VERSION ""

NS_ :

BS_:

BU_: BMS_CARRIER CENTRE_CONSOLE POWER_DISTRIBUTION_REAR POWER_DISTRIBUTION_FRONT MOTOR_CONTROLLER PEDAL STEERING SOLAR CHARGER IMU POWER_SELECTION BABYDRIVER

BO_ 1 BPS_HEARTBEAT: 1 BMS_CARRIER
 SG_ status : 0|8@1+ (1,0) [0|0] "" Vector__XXX

BO_ 18 BPS_HEARTBEAT_ACK_FROM_CENTRE_CONSOLE: 1 CENTRE_CONSOLE
 SG_ BPS_HEARTBEAT_FROM_CENTRE_CONSOLE_ACK_STATUS : 0|8@1+ (1,0) [0|0] "" Vector__XXX

BO_ 34 SET_RELAY_STATES: 4 CENTRE_CONSOLE
 SG_ relay_state : 16|16@1+ (1,0) [0|0] "" Vector__XXX
 SG_ relay_mask : 0|16@1+ (1,0) [0|0] "" Vector__XXX

BO_ 49 SET_RELAY_STATES_ACK_FROM_BMS_CARRIER: 1 BMS_CARRIER
 SG_ SET_RELAY_STATES_FROM_BMS_CARRIER_ACK_STATUS : 0|8@1+ (1,0) [0|0] "" Vector__XXX

BO_ 56 SET_RELAY_STATES_ACK_FROM_SOLAR: 1 SOLAR
 SG_ SET_RELAY_STATES_FROM_SOLAR_ACK_STATUS : 0|8@1+ (1,0) [0|0] "" Vector__XXX

BO_ 53 SET_RELAY_STATES_ACK_FROM_MOTOR_CONTROLLER: 1 MOTOR_CONTROLLER
 SG_ SET_RELAY_STATES_FROM_MOTOR_CONTROLLER_ACK_STATUS : 0|8@1+ (1,0) [0|0] "" Vector__XXX

BO_ 98 POWERTRAIN_HEARTBEAT: 0 CENTRE_CONSOLE

BO_ 117 POWERTRAIN_HEARTBEAT_ACK_FROM_MOTOR_CONTROLLER: 1 MOTOR_CONTROLLER
 SG_ POWERTRAIN_HEARTBEAT_FROM_MOTOR_CONTROLLER_ACK_STATUS : 0|8@1+ (1,0) [0|0] "" Vector__XXX

BO_ 118 POWERTRAIN_HEARTBEAT_ACK_FROM_PEDAL: 1 PEDAL
 SG_ POWERTRAIN_HEARTBEAT_FROM_PEDAL_ACK_STATUS : 0|8@1+ (1,0) [0|0] "" Vector__XXX

BO_ 130 GET_AUX_STATUS: 2 CENTRE_CONSOLE
 SG_ aux_bat_ut_flag : 8|8@1+ (1,0) [0|0] "" Vector__XXX
 SG_ aux_bat_ov_flag : 0|8@1+ (1,0) [0|0] "" Vector__XXX

BO_ 149 GET_AUX_STATUS_ACK_FROM_MOTOR_CONTROLLER: 1 MOTOR_CONTROLLER
 SG_ GET_AUX_STATUS_FROM_MOTOR_CONTROLLER_ACK_STATUS : 0|8@1+ (1,0) [0|0] "" Vector__XXX

BO_ 150 GET_AUX_STATUS_ACK_FROM_PEDAL: 1 PEDAL
 SG_ GET_AUX_STATUS_FROM_PEDAL_ACK_STATUS : 0|8@1+ (1,0) [0|0] "" Vector__XXX

BO_ 162 FAULT_SEQUENCE: 2 CENTRE_CONSOLE
 SG_ sequence : 0|16@1+ (1,0) [0|0] "" Vector__XXX

BO_ 181 FAULT_SEQUENCE_ACK_FROM_MOTOR_CONTROLLER: 1 MOTOR_CONTROLLER
 SG_ FAULT_SEQUENCE_FROM_MOTOR_CONTROLLER_ACK_STATUS : 0|8@1+ (1,0) [0|0] "" Vector__XXX

BO_ 182 FAULT_SEQUENCE_ACK_FROM_PEDAL: 1 PEDAL
 SG_ FAULT_SEQUENCE_FROM_PEDAL_ACK_STATUS : 0|8@1+ (1,0) [0|0] "" Vector__XXX

BO_ 194 POWER_ON_MAIN_SEQUENCE: 2 CENTRE_CONSOLE
 SG_ sequence : 0|16@1+ (1,0) [0|0] "" Vector__XXX

BO_ 213 POWER_ON_MAIN_SEQUENCE_ACK_FROM_MOTOR_CONTROLLER: 1 MOTOR_CONTROLLER
 SG_ POWER_ON_MAIN_SEQUENCE_FROM_MOTOR_CONTROLLER_ACK_STATUS : 0|8@1+ (1,0) [0|0] "" Vector__XXX

BO_ 214 POWER_ON_MAIN_SEQUENCE_ACK_FROM_PEDAL: 1 PEDAL
 SG_ POWER_ON_MAIN_SEQUENCE_FROM_PEDAL_ACK_STATUS : 0|8@1+ (1,0) [0|0] "" Vector__XXX

BO_ 226 POWER_OFF_SEQUENCE: 2 CENTRE_CONSOLE
 SG_ sequence : 0|16@1+ (1,0) [0|0] "" Vector__XXX

BO_ 245 POWER_OFF_SEQUENCE_ACK_FROM_MOTOR_CONTROLLER: 1 MOTOR_CONTROLLER
 SG_ POWER_OFF_SEQUENCE_FROM_MOTOR_CONTROLLER_ACK_STATUS : 0|8@1+ (1,0) [0|0] "" Vector__XXX

BO_ 246 POWER_OFF_SEQUENCE_ACK_FROM_PEDAL: 1 PEDAL
 SG_ POWER_OFF_SEQUENCE_FROM_PEDAL_ACK_STATUS : 0|8@1+ (1,0) [0|0] "" Vector__XXX

BO_ 258 POWER_ON_AUX_SEQUENCE: 2 CENTRE_CONSOLE
 SG_ sequence : 0|16@1+ (1,0) [0|0] "" Vector__XXX

BO_ 277 POWER_ON_AUX_SEQUENCE_ACK_FROM_MOTOR_CONTROLLER: 1 MOTOR_CONTROLLER
 SG_ POWER_ON_AUX_SEQUENCE_FROM_MOTOR_CONTROLLER_ACK_STATUS : 0|8@1+ (1,0) [0|0] "" Vector__XXX

BO_ 278 POWER_ON_AUX_SEQUENCE_ACK_FROM_PEDAL: 1 PEDAL
 SG_ POWER_ON_AUX_SEQUENCE_FROM_PEDAL_ACK_STATUS : 0|8@1+ (1,0) [0|0] "" Vector__XXX

BO_ 290 DRIVE_OUTPUT: 2 CENTRE_CONSOLE
 SG_ drive_output : 0|16@1+ (1,0) [0|0] "" Vector__XXX

BO_ 309 DRIVE_OUTPUT_ACK_FROM_MOTOR_CONTROLLER: 1 MOTOR_CONTROLLER
 SG_ DRIVE_OUTPUT_FROM_MOTOR_CONTROLLER_ACK_STATUS : 0|8@1+ (1,0) [0|0] "" Vector__XXX

BO_ 322 SET_EBRAKE_STATE: 1 CENTRE_CONSOLE
 SG_ ebrake_state : 0|8@1+ (1,0) [0|0] "" Vector__XXX

BO_ 322 SET_EBRAKE_STATE: 1 CENTRE_CONSOLE
 SG_ ebrake_state : 0|8@1+ (1,0) [0|0] "" Vector__XXX

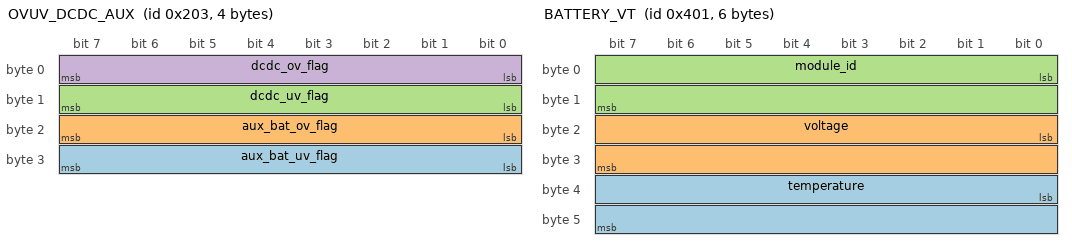
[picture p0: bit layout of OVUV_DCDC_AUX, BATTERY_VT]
BO_ 515 OVUV_DCDC_AUX: 4 POWER_DISTRIBUTION_REAR
 SG_ aux_bat_uv_flag : 24|8@1+ (1,0) [0|0] "" Vector__XXX
 SG_ aux_bat_ov_flag : 16|8@1+ (1,0) [0|0] "" Vector__XXX
 SG_ dcdc_uv_flag : 8|8@1+ (1,0) [0|0] "" Vector__XXX
 SG_ dcdc_ov_flag : 0|8@1+ (1,0) [0|0] "" Vector__XXX

BO_ 549 MC_ERROR_LIMITS: 4 MOTOR_CONTROLLER
 SG_ limits : 16|16@1+ (1,0) [0|0] "" Vector__XXX
 SG_ error_id : 0|16@1+ (1,0) [0|0] "" Vector__XXX

BO_ 582 PEDAL_OUTPUT: 8 PEDAL
 SG_ brake_output : 32|32@1+ (1,0) [0|0] "" Vector__XXX
 SG_ throttle_output : 0|32@1+ (1,0) [0|0] "" Vector__XXX

BO_ 615 CRUISE_TARGET: 1 STEERING
 SG_ target_speed : 0|8@1+ (1,0) [0|0] "" Vector__XXX

BO_ 646 BRAKE: 2 PEDAL
 SG_ brake_state : 0|16@1+ (1,0) [0|0] "" Vector__XXX

BO_ 674 FRONT_POWER: 2 CENTRE_CONSOLE
 SG_ power_bitset : 0|16@1+ (1,0) [0|0] "" Vector__XXX

BO_ 709 DRIVE_STATE: 2 MOTOR_CONTROLLER
 SG_ drive_state : 0|16@1+ (1,0) [0|0] "" Vector__XXX

BO_ 739 LIGHTS_SYNC: 0 POWER_DISTRIBUTION_REAR

BO_ 775 LIGHTS: 2 STEERING
 SG_ state : 8|8@1+ (1,0) [0|0] "" Vector__XXX
 SG_ lights_id : 0|8@1+ (1,0) [0|0] "" Vector__XXX

BO_ 807 HORN: 1 STEERING
 SG_ state : 0|8@1+ (1,0) [0|0] "" Vector__XXX

BO_ 842 GET_CHARGER_CONNECTION_STATE: 1 CHARGER
 SG_ is_connected : 0|8@1+ (1,0) [0|0] "" Vector__XXX

BO_ 866 SET_CHARGER_RELAY: 1 CENTRE_CONSOLE
 SG_ state : 0|8@1+ (1,0) [0|0] "" Vector__XXX

BO_ 898 BEGIN_PRECHARGE: 0 CENTRE_CONSOLE

BO_ 933 PRECHARGE_COMPLETED: 0 MOTOR_CONTROLLER

BO_ 962 HAZARD: 1 CENTRE_CONSOLE
 SG_ state : 0|8@1+ (1,0) [0|0] "" Vector__XXX

BO_ 994 DISCHARGE_PRECHARGE: 0 CENTRE_CONSOLE

BO_ 1025 BATTERY_VT: 6 BMS_CARRIER
 SG_ temperature : 32|16@1+ (1,0) [0|0] "" Vector__XXX
 SG_ voltage : 16|16@1+ (1,0) [0|0] "" Vector__XXX
 SG_ module_id : 0|16@1+ (1,0) [0|0] "" Vector__XXX

BO_ 1057 BATTERY_AGGREGATE_VC: 8 BMS_CARRIER
 SG_ current : 32|32@1+ (1,0) [0|0] "" Vector__XXX
 SG_ voltage : 0|32@1+ (1,0) [0|0] "" Vector__XXX

BO_ 1090 STATE_TRANSITION_FAULT: 4 CENTRE_CONSOLE
 SG_ fault_reason : 16|16@1+ (1,0) [0|0] "" Vector__XXX
 SG_ state_machine : 0|16@1+ (1,0) [0|0] "" Vector__XXX

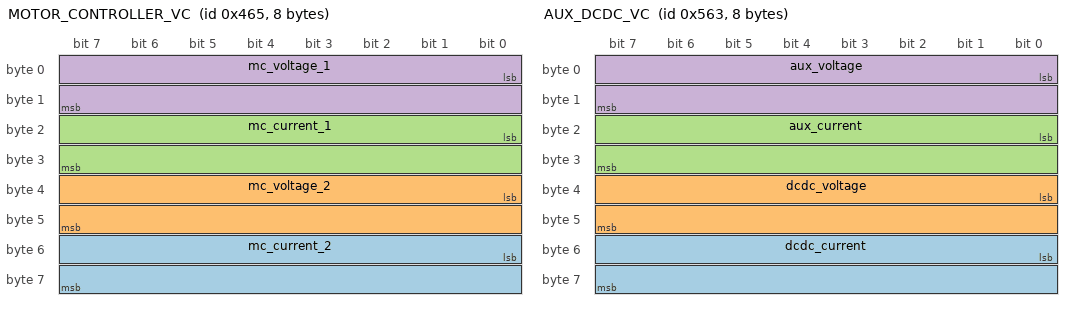
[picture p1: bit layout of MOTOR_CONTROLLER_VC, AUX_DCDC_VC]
BO_ 1125 MOTOR_CONTROLLER_VC: 8 MOTOR_CONTROLLER
 SG_ mc_current_2 : 48|16@1+ (1,0) [0|0] "" Vector__XXX
 SG_ mc_voltage_2 : 32|16@1+ (1,0) [0|0] "" Vector__XXX
 SG_ mc_current_1 : 16|16@1+ (1,0) [0|0] "" Vector__XXX
 SG_ mc_voltage_1 : 0|16@1+ (1,0) [0|0] "" Vector__XXX

BO_ 1157 MOTOR_VELOCITY: 4 MOTOR_CONTROLLER
 SG_ vehicle_velocity_right : 16|16@1+ (1,0) [0|0] "" Vector__XXX
 SG_ vehicle_velocity_left : 0|16@1+ (1,0) [0|0] "" Vector__XXX

BO_ 1189 MOTOR_DEBUG: 8 MOTOR_CONTROLLER
 SG_ data : 0|64@1+ (1,0) [0|0] "" Vector__XXX

BO_ 1221 MOTOR_TEMPS: 8 MOTOR_CONTROLLER
 SG_ motor_temp_r : 32|32@1+ (1,0) [0|0] "" Vector__XXX
 SG_ motor_temp_l : 0|32@1+ (1,0) [0|0] "" Vector__XXX

BO_ 1253 MOTOR_AMP_HR: 8 MOTOR_CONTROLLER
 SG_ motor_amp_hr_r : 32|32@1+ (1,0) [0|0] "" Vector__XXX
 SG_ motor_amp_hr_l : 0|32@1+ (1,0) [0|0] "" Vector__XXX

BO_ 1285 ODOMETER: 4 MOTOR_CONTROLLER
 SG_ odometer_val : 0|32@1+ (1,0) [0|0] "" Vector__XXX

BO_ 1319 CRUISE_CONTROL_COMMAND: 1 STEERING
 SG_ command : 0|8@1+ (1,0) [0|0] "" Vector__XXX

BO_ 1379 AUX_DCDC_VC: 8 POWER_DISTRIBUTION_REAR
 SG_ dcdc_current : 48|16@1+ (1,0) [0|0] "" Vector__XXX
 SG_ dcdc_voltage : 32|16@1+ (1,0) [0|0] "" Vector__XXX
 SG_ aux_current : 16|16@1+ (1,0) [0|0] "" Vector__XXX
 SG_ aux_voltage : 0|16@1+ (1,0) [0|0] "" Vector__XXX

BO_ 1411 DCDC_TEMPS: 4 POWER_DISTRIBUTION_REAR
 SG_ temp_2 : 16|16@1+ (1,0) [0|0] "" Vector__XXX
 SG_ temp_1 : 0|16@1+ (1,0) [0|0] "" Vector__XXX

BO_ 1444 UV_CUTOFF_NOTIFICATION: 0 POWER_DISTRIBUTION_FRONT

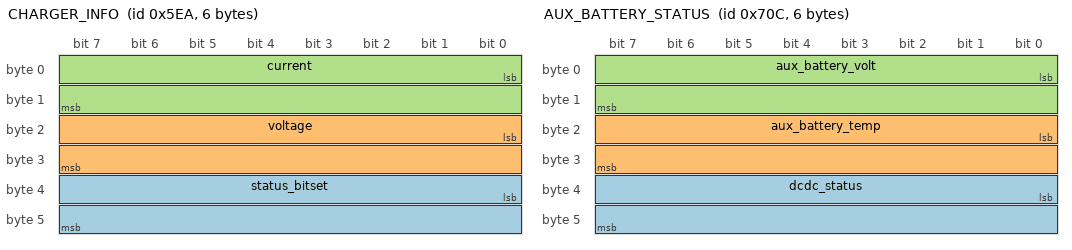
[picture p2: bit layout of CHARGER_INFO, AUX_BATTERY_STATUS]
BO_ 1514 CHARGER_INFO: 6 CHARGER
 SG_ status_bitset : 32|16@1+ (1,0) [0|0] "" Vector__XXX
 SG_ voltage : 16|16@1+ (1,0) [0|0] "" Vector__XXX
 SG_ current : 0|16@1+ (1,0) [0|0] "" Vector__XXX

BO_ 1546 REQUEST_TO_CHARGE: 0 CHARGER

BO_ 1570 ALLOW_CHARGING: 0 CENTRE_CONSOLE

BO_ 1610 CHARGER_CONNECTED_STATE: 1 CHARGER
 SG_ is_connected : 0|8@1+ (1,0) [0|0] "" Vector__XXX

BO_ 1643 LINEAR_ACCELERATION: 0 IMU

BO_ 1675 ANGULAR_ROTATION: 0 IMU

BO_ 1706 CHARGER_FAULT: 1 CHARGER
 SG_ fault : 0|8@1+ (1,0) [0|0] "" Vector__XXX

BO_ 1732 FRONT_CURRENT_MEASUREMENT: 4 POWER_DISTRIBUTION_FRONT
 SG_ current : 16|16@1+ (1,0) [0|0] "" Vector__XXX
 SG_ current_id : 0|16@1+ (1,0) [0|0] "" Vector__XXX

BO_ 1763 REAR_CURRENT_MEASUREMENT: 4 POWER_DISTRIBUTION_REAR
 SG_ current : 16|16@1+ (1,0) [0|0] "" Vector__XXX
 SG_ current_id : 0|16@1+ (1,0) [0|0] "" Vector__XXX

BO_ 1804 AUX_BATTERY_STATUS: 6 POWER_SELECTION
 SG_ dcdc_status : 32|16@1+ (1,0) [0|0] "" Vector__XXX
 SG_ aux_battery_temp : 16|16@1+ (1,0) [0|0] "" Vector__XXX
 SG_ aux_battery_volt : 0|16@1+ (1,0) [0|0] "" Vector__XXX

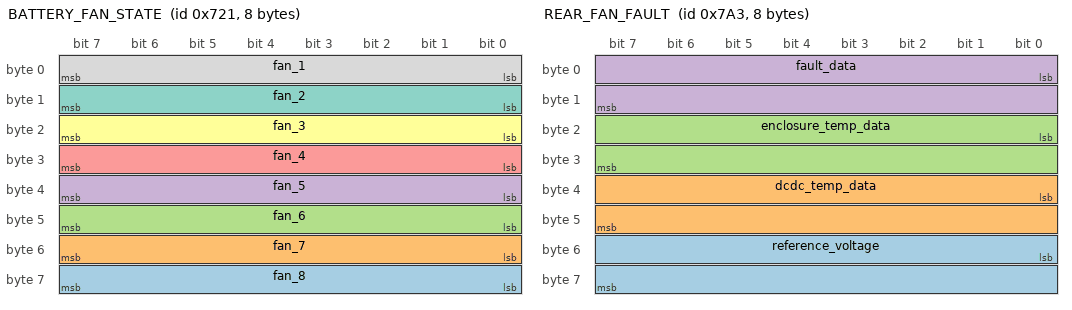
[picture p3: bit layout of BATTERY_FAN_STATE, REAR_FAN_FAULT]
BO_ 1825 BATTERY_FAN_STATE: 8 BMS_CARRIER
 SG_ fan_8 : 56|8@1+ (1,0) [0|0] "" Vector__XXX
 SG_ fan_7 : 48|8@1+ (1,0) [0|0] "" Vector__XXX
 SG_ fan_6 : 40|8@1+ (1,0) [0|0] "" Vector__XXX
 SG_ fan_5 : 32|8@1+ (1,0) [0|0] "" Vector__XXX
 SG_ fan_4 : 24|8@1+ (1,0) [0|0] "" Vector__XXX
 SG_ fan_3 : 16|8@1+ (1,0) [0|0] "" Vector__XXX
 SG_ fan_2 : 8|8@1+ (1,0) [0|0] "" Vector__XXX
 SG_ fan_1 : 0|8@1+ (1,0) [0|0] "" Vector__XXX

BO_ 1857 BATTERY_RELAY_STATE: 2 BMS_CARRIER
 SG_ gnd : 8|8@1+ (1,0) [0|0] "" Vector__XXX
 SG_ hv : 0|8@1+ (1,0) [0|0] "" Vector__XXX

BO_ 1896 SOLAR_DATA: 8 SOLAR
 SG_ data_value : 32|32@1+ (1,0) [0|0] "" Vector__XXX
 SG_ data_point_type : 0|32@1+ (1,0) [0|0] "" Vector__XXX

BO_ 1928 SOLAR_FAULT: 2 SOLAR
 SG_ fault_data : 8|8@1+ (1,0) [0|0] "" Vector__XXX
 SG_ fault : 0|8@1+ (1,0) [0|0] "" Vector__XXX

BO_ 1955 REAR_FAN_FAULT: 8 POWER_DISTRIBUTION_REAR
 SG_ reference_voltage : 48|16@1+ (1,0) [0|0] "" Vector__XXX
 SG_ dcdc_temp_data : 32|16@1+ (1,0) [0|0] "" Vector__XXX
 SG_ enclosure_temp_data : 16|16@1+ (1,0) [0|0] "" Vector__XXX
 SG_ fault_data : 0|16@1+ (1,0) [0|0] "" Vector__XXX

BO_ 1988 FRONT_FAN_FAULT: 2 POWER_DISTRIBUTION_FRONT
 SG_ fault_data : 0|16@1+ (1,0) [0|0] "" Vector__XXX

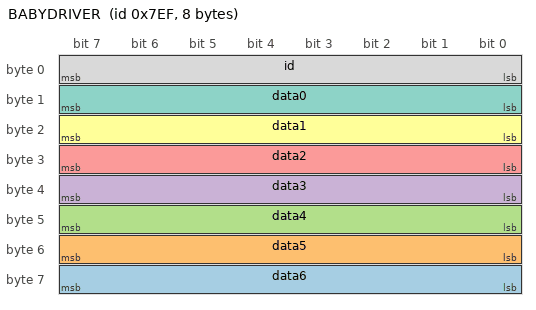
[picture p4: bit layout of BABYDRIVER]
BO_ 2031 BABYDRIVER: 8 BABYDRIVER
 SG_ data6 : 56|8@1+ (1,0) [0|0] "" Vector__XXX
 SG_ data5 : 48|8@1+ (1,0) [0|0] "" Vector__XXX
 SG_ data4 : 40|8@1+ (1,0) [0|0] "" Vector__XXX
 SG_ data3 : 32|8@1+ (1,0) [0|0] "" Vector__XXX
 SG_ data2 : 24|8@1+ (1,0) [0|0] "" Vector__XXX
 SG_ data1 : 16|8@1+ (1,0) [0|0] "" Vector__XXX
 SG_ data0 : 8|8@1+ (1,0) [0|0] "" Vector__XXX
 SG_ id : 0|8@1+ (1,0) [0|0] "" Vector__XXX

CM_ BU_ BMS_CARRIER "Device ID: 0x1";
CM_ BU_ CENTRE_CONSOLE "Device ID: 0x2";
CM_ BU_ POWER_DISTRIBUTION_REAR "Device ID: 0x3";
CM_ BU_ POWER_DISTRIBUTION_FRONT "Device ID: 0x4";
CM_ BU_ MOTOR_CONTROLLER "Device ID: 0x5";
CM_ BU_ PEDAL "Device ID: 0x6";
CM_ BU_ STEERING "Device ID: 0x7";
CM_ BU_ SOLAR "Device ID: 0x8";
CM_ BU_ CHARGER "Device ID: 0xa";
CM_ BU_ IMU "Device ID: 0xb";
CM_ BU_ POWER_SELECTION "Device ID: 0xc";
CM_ BU_ BABYDRIVER "Device ID: 0xf";
